# LPC8N04 register map
File version: 0.1
CPU: CM0PLUS r0p0, little endian, no MPU, no FPU, 2 interrupt priority bits
Registers are 32-bit, read-write, no defined reset value unless marked. A register's access mark holds for its fields unless they carry their own. Offsets are from the block's base; [hi:lo] are bit positions; 'fields as' and 'values as' point back to an identical list.

## IOCON — IO configuration
Base 0x40044000
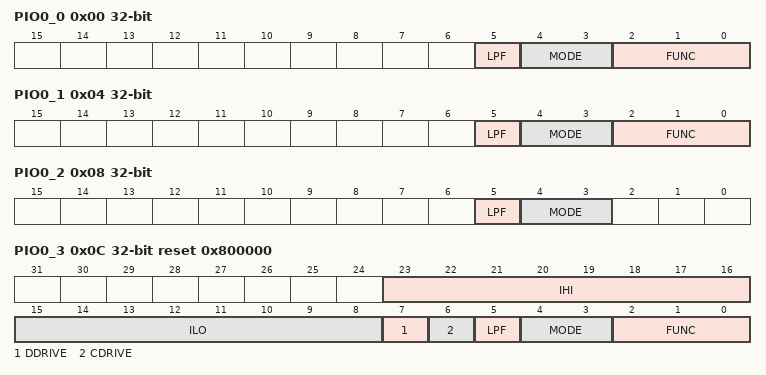
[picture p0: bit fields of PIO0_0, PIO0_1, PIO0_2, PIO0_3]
0x00 PIO0_0 — Pin PIO0_0 / WAKEUP (+ JTAG TCK)
  [5] LPF — Low-pass filter
    0=DISABLED; 1=ENABLED
  [4:3] MODE — Selects function mode (on-chip pull-up/pull-down resistor control)
    0=INACTIVE (inactive (no pull-up/down resistor enabled)); 1=PULLDOWN (Pull-down resistor enabled); 2=PULLUP (Pull-up resistor enabled); 3=REPEATER (Repeater mode)
  [2:0] FUNC — Selects pin function. All other values are reserved
    0=PIO0_0; 1=WAKEUP
0x04 PIO0_1 — Pin PIO0_1 / CLKOUT (+ JTAG TMS)
  [5] LPF — Low-pass filter
    0=DISABLED; 1=ENABLED
  [4:3] MODE — Selects function mode (on-chip pull-up/pull-down resistor control)
    values as PIO0_0.MODE
  [2:0] FUNC — Selects pin function. All other values are reserved
    0=PIO0_1; 1=CLKOUT
0x08 PIO0_2 — Pin PIO0_2 / SPI SSEL (+ JTAG TDI)
  [5] LPF — Low-pass filter
    0=DISABLED; 1=ENABLED
  [4:3] MODE — Selects function mode (on-chip pull-up/pull-down resistor control)
    values as PIO0_0.MODE
0x0C PIO0_3 reset 0x800000 (reset mask 0x0) — Pin PIO0_3 / CT16B_M0
  [23:16] IHI — Output high (asserted) value
  [15:8] ILO — Output low (deasserted) value
  [7] DDRIVE — Digital drive strength
    0=HIGH (High Drive (pad EHD0=0,EHD1=1)); 1=ULTRAHIGH (Ultra high Drive (pad EHD0=1,EHD1=1))
  [6] CDRIVE — Select pin output driver
    0=FIXED (Fixed voltage driver); 1=PROGRAMMABLE (Programmable current driver)
  [5] LPF — Low-pass filter
    0=DISABLED; 1=ENABLED
  [4:3] MODE — Selects function mode (on-chip pull-up/pull-down resistor control)
    values as PIO0_0.MODE
  [2:0] FUNC — Selects pin function. All other values are reserved
    0=PIO0_3; 1=CT16B_M0
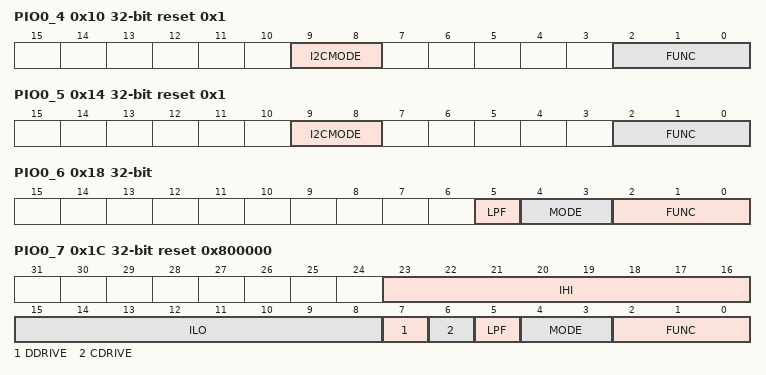
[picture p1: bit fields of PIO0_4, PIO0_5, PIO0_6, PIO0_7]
0x10 PIO0_4 reset 0x1 (reset mask 0x0) — Pin PIO0_4 / I2C SCL
  [9:8] I2CMODE — Selects I2C mode. Select Standard mode I2CMODE = 00, default) or Standard I/O functionality (I2CMODE = 01) if the pin function is GPIO (FUNC = 000).
    0=STD_FAST_I2C (Standard mode/fast-mode I2C); 1=STD_I_O (Standard I/O functionality)
  [2:0] FUNC — Selects pin function. All other values are reserved
    0=PIO0_4 (PIO0_4 (open-drain pin)); 1=I2C_SCL (I2C SCL (open-drain pin))
0x14 PIO0_5 reset 0x1 (reset mask 0x0) — Pin PIO0_5 / I2C SDA
  [9:8] I2CMODE — Selects I2C mode. Select Standard mode I2CMODE = 00, default) or Standard I/O functionality (I2CMODE = 01) if the pin function is GPIO (FUNC = 000).
    values as PIO0_4.I2CMODE
  [2:0] FUNC — Selects pin function. All other values are reserved
    0=PIO0_5 (PIO0_5 (open-drain pin)); 1=I2C_SDA (I2C SDA (open-drain pin))
0x18 PIO0_6 — Pin PIO0_6 / SPI SCLK (+ JTAG TDO)
  [5] LPF — Low-pass filter
    0=DISABLED; 1=ENABLED
  [4:3] MODE — Selects function mode (on-chip pull-up/pull-down resistor control)
    values as PIO0_0.MODE
  [2:0] FUNC — Selects pin function. All other values are reserved
    0=PIO0_6; 1=SPI_SCLK (SPI/SSP SCLK)
0x1C PIO0_7 reset 0x800000 (reset mask 0x0) — Pin PIO0_7 / CT16B_M1
  [23:16] IHI — Output high (asserted) value
  [15:8] ILO — Output low (deasserted) value
  [7] DDRIVE — Digital drive strength
    values as PIO0_3.DDRIVE
  [6] CDRIVE — Select pin output driver
    values as PIO0_3.CDRIVE
  [5] LPF — Low-pass filter
    0=DISABLED; 1=ENABLED
  [4:3] MODE — Selects function mode (on-chip pull-up/pull-down resistor control)
    values as PIO0_0.MODE
  [2:0] FUNC — Selects pin function. All other values are reserved
    0=PIO0_7; 1=CT16B_M1
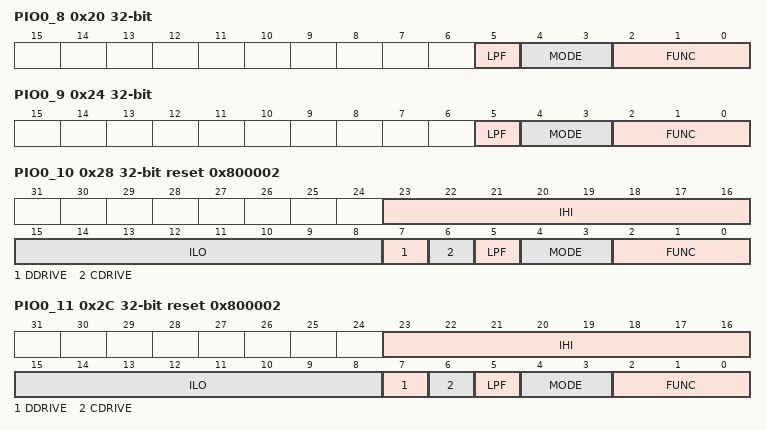
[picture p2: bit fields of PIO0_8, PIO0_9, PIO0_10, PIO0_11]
0x20 PIO0_8 — Pin PIO0_8 / SPI MISO (+ SCOUT1)
  [5] LPF — Low-pass filter
    0=DISABLED; 1=ENABLED
  [4:3] MODE — Selects function mode (on-chip pull-up/pull-down resistor control)
    values as PIO0_0.MODE
  [2:0] FUNC — Selects pin function. All other values are reserved
    0=PIO0_8; 1=SPI_MISO (SPI/SSP MISO)
0x24 PIO0_9 — Pin PIO0_9 / SPI MOSI (+ SCIN2)
  [5] LPF — Low-pass filter
    0=DISABLED; 1=ENABLED
  [4:3] MODE — Selects function mode (on-chip pull-up/pull-down resistor control)
    values as PIO0_0.MODE
  [2:0] FUNC — Selects pin function. All other values are reserved
    0=PIO0_9; 1=SPI_MOSI (SPI/SSP MOSI)
0x28 PIO0_10 reset 0x800002 (reset mask 0x0) — Pin PIO0_10 / CT32B_M0 / SWCLK (+ SCOUT2)
  [23:16] IHI — Output high (asserted) value
  [15:8] ILO — Output low (deasserted) value
  [7] DDRIVE — Digital drive strength
    values as PIO0_3.DDRIVE
  [6] CDRIVE — Select pin output driver
    values as PIO0_3.CDRIVE
  [5] LPF — Low-pass filter
    0=DISABLED; 1=ENABLED
  [4:3] MODE — Selects function mode (on-chip pull-up/pull-down resistor control)
    values as PIO0_0.MODE
  [2:0] FUNC — Selects pin function. All other values are reserved
    0=PIO0_10; 1=CT32B_M0; 2=SWCLK
0x2C PIO0_11 reset 0x800002 (reset mask 0x0) — Pin PIO0_11 / CT32B_M1 / SWDIO (+ SCIN1)
  [23:16] IHI — Output high (asserted) value
  [15:8] ILO — Output low (deasserted) value
  [7] DDRIVE — Digital drive strength
    values as PIO0_3.DDRIVE
  [6] CDRIVE — Select pin output driver
    values as PIO0_3.CDRIVE
  [5] LPF — Low pass filter
    0=DISABLED; 1=ENABLED
  [4:3] MODE — Selects function mode (on-chip pull-up/pull-down resistor control)
    values as PIO0_0.MODE
  [2:0] FUNC — Selects pin function. All other values are reserved
    0=PIO0_11; 1=CT32B_M1; 2=SWDIO
